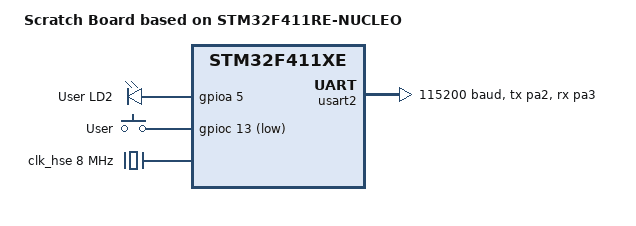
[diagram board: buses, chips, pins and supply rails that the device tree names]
/dts-v1/;
#include <st/f4/stm32f411Xe.dtsi>
#include <st/f4/stm32f411r(c-e)tx-pinctrl.dtsi>
#include <zephyr/dt-bindings/input/input-event-codes.h>

/ {
    model = "Scratch Board based on STM32F411RE-NUCLEO";
    compatible = "bugi,scratch_board";

    chosen{
        zephyr,console = &usart2;
		zephyr,shell-uart = &usart2;
		zephyr,sram = &sram0;
		zephyr,flash = &flash0;
    };

    	leds: leds {
		compatible = "gpio-leds";

		green_led_2: led_2 {
			gpios = <&gpioa 5 GPIO_ACTIVE_HIGH>;
			label = "User LD2";
		};
	};

   gpio_keys {
		compatible = "gpio-keys";

		user_button: button {
			label = "User";
			gpios = <&gpioc 13 GPIO_ACTIVE_LOW>;
			zephyr,code = <INPUT_KEY_0>;
		};
	}; 

    aliases{
        heartbeat-led = &green_led_2;
        btn= &user_button;
    };

};

&clk_lsi {
	status = "okay";
};

&clk_hse {
	hse-bypass;
	clock-frequency = <DT_FREQ_M(8)>; /* STLink 8MHz clock */
	status = "okay";
};

&pll {
	div-m = <8>;
	mul-n = <384>;
	div-p = <4>;
	div-q = <8>;
	clocks = <&clk_hse>;
	status = "okay";
};

&rcc {
	clocks = <&pll>;
	clock-frequency = <DT_FREQ_M(96)>;
	ahb-prescaler = <1>;
	apb1-prescaler = <2>;
	apb2-prescaler = <1>;
};

&usart2 {
	pinctrl-0 = <&usart2_tx_pa2 &usart2_rx_pa3>;
	pinctrl-names = "default";
	current-speed = <115200>;
	status = "okay";
};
